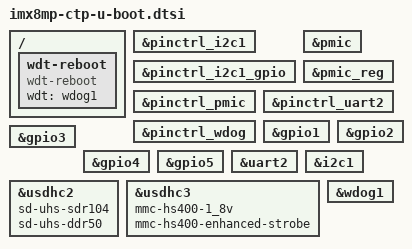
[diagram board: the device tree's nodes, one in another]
// SPDX-License-Identifier: (GPL-2.0-or-later OR MIT)
/*
 * Copyright 2025 Ezurio
 */

#include "imx8mp-u-boot.dtsi"

/ {
	wdt-reboot {
		compatible = "wdt-reboot";
		wdt = <&wdog1>;
		bootph-pre-ram;
	};
};

&pinctrl_i2c1 {
	bootph-all;
};

&pinctrl_i2c1_gpio {
	bootph-all;
};

&pinctrl_pmic {
	bootph-all;
};

&pmic {
	bootph-all;
};

&pmic_reg {
	bootph-all;
};

&pinctrl_uart2 {
	bootph-pre-ram;
};

&pinctrl_wdog {
	bootph-pre-ram;
};

&gpio1 {
	bootph-pre-ram;
};

&gpio2 {
	bootph-pre-ram;
};

&gpio3 {
	bootph-pre-ram;
};

&gpio4 {
	bootph-pre-ram;
};

&gpio5 {
	bootph-pre-ram;
};

&uart2 {
	bootph-pre-ram;
};

&i2c1 {
	bootph-all;
};

&usdhc2 {
	bootph-pre-ram;
	sd-uhs-sdr104;
	sd-uhs-ddr50;
};

&usdhc3 {
	bootph-pre-ram;
	mmc-hs400-1_8v;
	mmc-hs400-enhanced-strobe;
};

&wdog1 {
	bootph-pre-ram;
};
